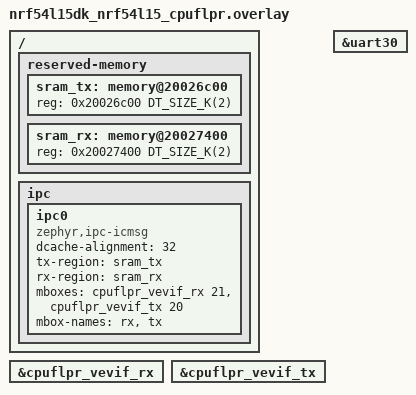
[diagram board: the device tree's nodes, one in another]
/*
 * Copyright (c) 2025 Nordic Semiconductor ASA
 *
 * SPDX-License-Identifier: LicenseRef-Nordic-5-Clause
 */

/ {
	reserved-memory {
		#address-cells = <1>;
		#size-cells = <1>;
		ranges;

		sram_tx: memory@20026c00 {
			reg = <0x20026c00 DT_SIZE_K(2)>;
		};

		sram_rx: memory@20027400 {
			reg = <0x20027400 DT_SIZE_K(2)>;
		};
	};

	ipc {
		ipc0: ipc0 {
			compatible = "zephyr,ipc-icmsg";
			dcache-alignment = <32>;
			tx-region = <&sram_tx>;
			rx-region = <&sram_rx>;
			mboxes = <&cpuflpr_vevif_rx 21>, <&cpuflpr_vevif_tx 20>;
			mbox-names = "rx", "tx";
			status = "okay";
		};
	};
};

&cpuflpr_vevif_rx {
	status = "okay";
};

&cpuflpr_vevif_tx {
	status = "okay";
};

&uart30 {
	/delete-property/ hw-flow-control;
};
